# psc3_p8 register map
Vendor: Infineon Technologies; Series: PSC3_P8; File version: 1.0
CPU: CM33 r0p1, little endian, MPU, FPU, DSP, VTOR, 3 interrupt priority bits, 143 interrupts
Registers are 32-bit, read-write, reset 0x0 unless marked. A register's access mark holds for its fields unless they carry their own. Offsets are from the block's base; [hi:lo] are bit positions; lines under a group give offsets from that group; {n}, {i} and the like mark numbered series.

## PPCA_CNFG
Base 0x43000000
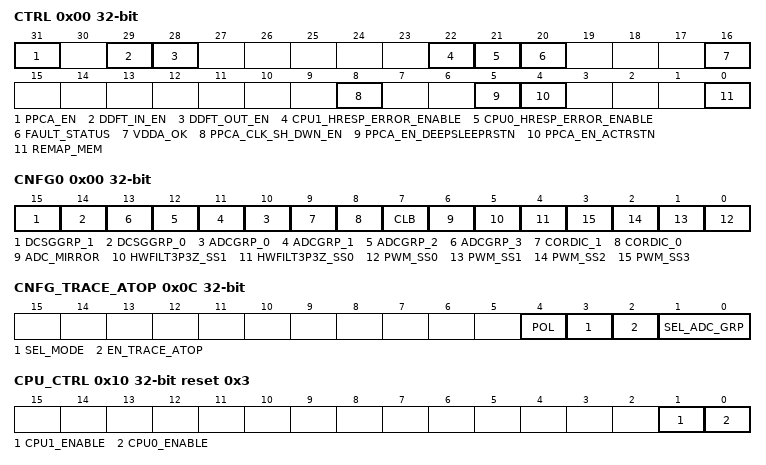
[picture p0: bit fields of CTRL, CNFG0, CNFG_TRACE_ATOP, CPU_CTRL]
0x00 CTRL
  [31] PPCA_EN — PPCA Enable/Disable register 0 = PPCA disabled, all the internal clock are gated, all registers are reset 1 = PPCA enabled
  [29] DDFT_IN_EN — Enable DDFT_IN: 0 = DDFT_IN disable 1 = DDFT_IN enable
  [28] DDFT_OUT_EN — Enable DDFT_OUT: 0 = DDFT_OUT disable 1 = DDFT_OUT enable
  [22] CPU1_HRESP_ERROR_ENABLE — CPU1 HRESP ERROR propagation as Fault Enable Control register 0 = CPU1 HRESP ERROR FAULT Disable 1 = CPU1 HRESP ERROR FAULT Enable
  [21] CPU0_HRESP_ERROR_ENABLE — CPU0 HRESP ERROR propagation as Fault Enable Control register 0 = CPU0 HRESP ERROR FAULT Disable 1 = CPU0 HRESP ERROR FAULT Enable
  [20] FAULT_STATUS write-1-clears — Reflect status of the Fault: 0 = no fault 1 = fault active Writing 1 on this bit clear the fault
  [16] VDDA_OK ro — PPCA VDDA Domain Voltage Status: 0 = VDDA not in the functional operation voltage range 1 = VDDA is in the functional operation voltage range
  [8] PPCA_CLK_SH_DWN_EN — PPCA Clock Shut Down Enable: 0 = Disable Clock Shut Down 1 = Enable Clock Shut Down
  [5] PPCA_EN_DEEPSLEEPRSTN — Enable/Disable PPCA_EN bit to reset PPCA retained logic: 0 = Disable 1 = Enable
  [4] PPCA_EN_ACTRSTN — Enable/Disable PPCA_EN bit to reset PPCA non-retained (active) logic: 0 = Disable 1 = Enable
  [0] REMAP_MEM — PPCA BusMatrix Remap Bit: 0 = Dedicated memories assigned for CPU0 and CPU1 1 = CPU1 memories reassigned to CPU0 memories
0x100 CNFG group
  0x00 CNFG0
    [15] DCSGGRP_1 — PPCA Configuration Register 0 = DCSGGRP_1 assigned to CPU0 1 = DCSGGRP_1 assigned to CPU1
    [14] DCSGGRP_0 — PPCA Configuration Register 0 = DCSGGRP_0 assigned to CPU0 1 = DCSGGRP_0 assigned to CPU1
    [n+10] ADCGRP_{n} (n=0..3) — PPCA Configuration Register 0 = ADCGRP_{n} assigned to CPU0 1 = ADCGRP_{n} assigned to CPU1
    [9] CORDIC_1 — PPCA Configuration Register 0 = CORDIC_1 assigned to CPU0 1 = CORDIC_1 assigned to CPU1
    [8] CORDIC_0 — PPCA Configuration Register 0 = CORDIC_0 assigned to CPU0 1 = CORDIC_0 assigned to CPU1
    [7] CLB — PPCA Configuration Register 0 = CLB assigned to CPU0 1 = CLB assigned to CPU1
    [6] ADC_MIRROR — PPCA Configuration Register 0 = ADC_MIRROR assigned to CPU0 1 = ADC_MIRROR assigned to CPU1
    [5] HWFILT3P3Z_SS1 — PPCA Configuration Register 0 = HWFILT3P3Z_SS1 assigned to CPU0 1 = HWFILT3P3Z_SS1 assigned to CPU1
    [4] HWFILT3P3Z_SS0 — PPCA Configuration Register 0 = HWFILT3P3Z_SS0 assigned to CPU0 1 = HWFILT3P3Z_SS0 assigned to CPU1
    [n] PWM_SS{n} (n=0..3) — PPCA Configuration Register 0 = PWM_SS{n} assigned to CPU0 1 = PWM_SS{n} assigned to CPU1
  0x04 CNFG1
    [31:0] CNFG_PUTY1 — PPCA EPU PU TYPE1 Resources Configuration Register CNFG_PUTY1[i] = 0, assign PUTY1 'i' to CPU0 CNFG_PUTY1[i] = 1, assign PUTY1 'i' to CPU1
  0x08 CNFG2
    [15:0] CNFG_PUTY2 — PPCA EPU Resources PU TYPE2 Configuration Register CNFG_PUTY2[i] = 0, assign PUTY2 'i' to CPU0 CNFG_PUTY2[i] = 1, assign PUTY2 'i' to CPU1
  0x0C CNFG_TRACE_ATOP
    [4] POL — Invert polarity of STB_STRETCH signal: 0 = Rising edge aligned with the data change 1 = Falling edge aligned with data chnage
    [3] SEL_MODE — Select TRACE_ATOP Mode: 0 = TRACE_ATOP test mode (adc data splitted into two nibble, each one of 6 bit) 1 = TRACE_ATOP functional mode (adc data planar exported)
    [2] EN_TRACE_ATOP — Enable TRACE_ATOP: 0 = TRACE_ATOP disable 1 = TRACE_ATOP enable
    [1:0] SEL_ADC_GRP — Select ADC Group source for TRACE_ATOP: 0 = ADC_GRP0 1 = ADC_GRP1 2 = ADC_GRP2 3 = ADC_GRP3
  0x10 CPU_CTRL reset 0x3
    [1] CPU1_ENABLE — CPU1 Enable Control register 0 = CPU1 Clock disable 1 = CPU0 Clock Enable
    [0] CPU0_ENABLE — CPU0 Enable Control register 0 = CPU0 Clock Disable 1 = CPU0 Clock Enable
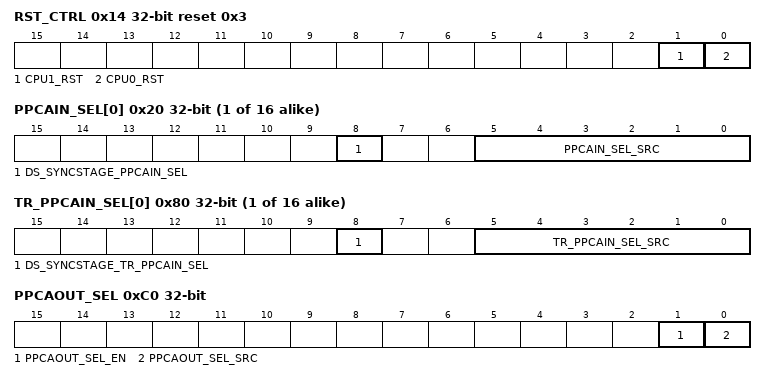
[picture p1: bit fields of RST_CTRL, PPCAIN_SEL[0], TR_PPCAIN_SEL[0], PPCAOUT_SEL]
  0x14 RST_CTRL reset 0x3
    [1] CPU1_RST — CPU1 Reset Control bit: 0 = Reset asserted 1 = Reset released
    [0] CPU0_RST — CPU0 Reset Control bit: 0 = CPU under reset 1 = CPU reset release
  {0x20+4j} PPCAIN_SEL[{j}] (j=0..15)
    [8] DS_SYNCSTAGE_PPCAIN_SEL — Disable PPCA Input Selector Output Synchronizer Stage 0 = Synchronizer Stage Enabled (2 FF in sequence) 1 = Synchronizer Stage Disabled (only 1 FF)
    [5:0] PPCAIN_SEL_SRC — PPCA Input Selector Source
  {0x80+4j} TR_PPCAIN_SEL[{j}] (j=0..15)
    [8] DS_SYNCSTAGE_TR_PPCAIN_SEL — Disable PPCA Trigger Input Selector Output Synchronizer Stage 0 = Synchronizer Stage Enabled (2 FF in sequence) 1 = Synchronizer Stage Disabled (only 1 FF)
    [5:0] TR_PPCAIN_SEL_SRC — PPCA Trigger Input Selector Source
  0xC0 PPCAOUT_SEL
    [1] PPCAOUT_SEL_EN — PPCA Output Selector Enabled 0 = Disabled (output se to 0) 1 = Enabled
    [0] PPCAOUT_SEL_SRC — PPCA Output Selector Source 0 = TCPWM output 1 = CLB output
  {0xE0+4j} DDFTOUT_SEL[{j}] (j=0..1)
    [8:0] DDFTOUT_SEL_SRC — PPCA DDFT Output Selector
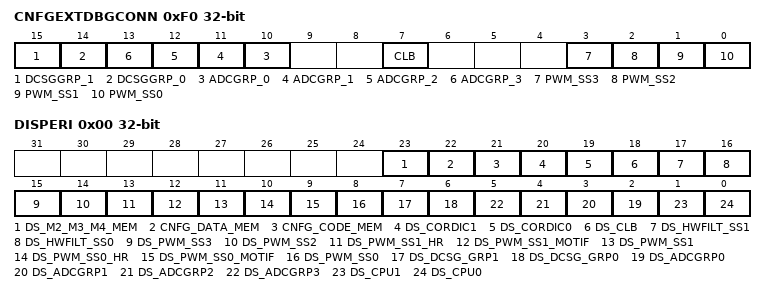
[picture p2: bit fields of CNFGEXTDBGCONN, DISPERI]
  0xF0 CNFGEXTDBGCONN
    [15] DCSGGRP_1 — PPCA EXT AHB IF Debug Conn Configuration Register 0 = DCSGGRP_1 assigned to Main CPU 1 = DCSGGRP_1 assigned to PPCA CPUs
    [14] DCSGGRP_0 — PPCA EXT AHB IF Debug Conn Configuration Register 0 = DCSGGRP_0 assigned to Main CPU 1 = DCSGGRP_0 assigned to PPCA CPUs
    [n+10] ADCGRP_{n} (n=0..3) — PPCA EXT AHB IF Debug Conn Configuration Register 0 = ADCGRP_{n} assigned to Main CPU 1 = ADCGRP_{n} assigned to PPCA CPUs
    [7] CLB — PPCA Configuration Register for ExtAHB Master IF 0 = CLB assigned to Main CPU 1 = CLB assigned to PPCA CPUs
    [3] PWM_SS3 — PPCA EXT AHB IF Debug Conn Configuration Register 0 = PWM_SS3 assigned to Main CPU 1 = PWM_SS3 assigned to PPCA CPUs
    [2] PWM_SS2 — PPCA EXT AHB IF Debug Conn Configuration Register 0 = PWM_SS2 assigned to Main CPU 1 = PWM_SS2 assigned to PPCA CPUs
    [1] PWM_SS1 — PPCA EXT AHB IF Debug Conn Configuration Register 0 = PWM_SS1 assigned to Main CPU 1 = PWM_SS1 assigned to PPCA CPUs
    [0] PWM_SS0 — PPCA EXT AHB IF Debug Conn Configuration Register 0 = PWM_SS0 assigned to MainCPU 1 = PWM_SS0 assigned to PPCA CPUs
  0xF4 PPCAIO_IN_MON ro
    [15:0] PPCAIO_IN_MON — PPCAIO_IN Monitor register (it reflect the status of PPCAIO Input signals synchronized with PPCA CLK)
  0xF8 SCRATCH0
    [31:0] SCRATCH0 — PPCA Scratch register
  0xFC SCRATCH1
    [31:0] SCRATCH1 — PPCA Scratch register
{0x300+0x10*i} S2IRQ[{i}] (i=0..6) group
  0x00 INTR — Interrupt Request Register
    [0] INTR write-1-clears — Interrupt requests
  0x04 INTR_SET — Interrupt Set Request Register
    [0] INTR_SET write-1-sets — Write INTR_SET field with '1' to set corresponding INTR field. When read, this register reflects the interrupt request register. That is the INTR register.
  0x08 INTR_MASK — Interrupt Mask Register
    [0] INTR_MASK — Mask for corresponding field in INTR register.
  0x0C INTR_MASKED ro — Interrupt Masked Register
    [0] INTR_MASKED — Logical AND of corresponding interrupt request (INTR) and mask fields (INTR_MASK).
0x400 ADCM group
  {0x0+4j} ADC_DATA[{j}] (j=0..47) ro
    [31:0] ADC_DATA — ADCs DATA Channel (ADC0_DATA, ADC0_AUX_DATA, ADC0_ALT_AUX_DATA, ADC1_DATA, ADC2_DATA, ADC3_DATA, ADC3_AUX_DATA)
0x800 DISPERI group
  0x00 DISPERI
    [23] DS_M2_M3_M4_MEM — Disable memory M2, M3, M4 (Light Configuration) 1 = M2, M3, M4 memories accesses are disabled 0 = M2, M3, M4 memories accesses are allowed
    [22] CNFG_DATA_MEM — Reduce CPUs Data Mem by half (shared mem not included) 1 = Data Mem is reduced by half 0 = Data Mem is not reduced
    [21] CNFG_CODE_MEM — Reflect instantiated CPUs Code Mem Size 1 = Code Mem is 32kB 0 = Code Mem is 64kB
    [20] DS_CORDIC1 — disable 2nd CORDIC 1 = 2nd CORDIC AHB memory space access is disabled 0 = 2nd CORDIC AHB memory space access is enabled
    [19] DS_CORDIC0 — disable 1st CORDIC 1 = 1st CORDIC AHB memory space access is disabled 0 = 1st CORDIC AHB memory space access is enabled
    [18] DS_CLB — disable CLB 1 = CLB AHB memory space access is disabled 0 = CLB AHB memory space access is enabled
    [17] DS_HWFILT_SS1 — disable HWFILT3P3Z SS1 1 = HWFILT3P3Z SS1 AHB memory space access is disabled 0 = HWFILT3P3Z SS1 AHB memory space access is enabled
    [16] DS_HWFILT_SS0 — disable HWFILT3P3Z SS0 1 = HWFILT3P3Z SS0 AHB memory space access is disabled 0 = HWFILT3P3Z SS0 AHB memory space access is enabled
    [15] DS_PWM_SS3 — disablePWM SS3 1 = PWM SS3 AHB memory space access is disabled 0 = PWM SS3 AHB memory space access is enabled
    [14] DS_PWM_SS2 — disablePWM SS2 1 = PWM SS2 AHB memory space access is disabled 0 = PWM SS2 AHB memory space access is enabled
    [13] DS_PWM_SS1_HR — disablePWM SS1 HR 1 = PWM SS1 HR AHB memory space access is disabled 0 = PWM SS1 HR AHB memory space access is enabled
    [12] DS_PWM_SS1_MOTIF — disablePWM SS1 MOTIF 1 = PWM SS1 MOTIF AHB memory space access is disabled 0 = PWM SS1 MOTIF AHB memory space access is enabled
    [11] DS_PWM_SS1 — disablePWM SS1 1 = PWM SS1 AHB memory space access is disabled 0 = PWM SS1 AHB memory space access is enabled
    [10] DS_PWM_SS0_HR — disablePWM SS0 HR 1 = PWM SS0 HR AHB memory space access is disabled 0 = PWM SS0 HR AHB memory space access is enabled
    [9] DS_PWM_SS0_MOTIF — disablePWM SS0 MOTIF 1 = PWM SS0 MOTIF AHB memory space access is disabled 0 = PWM SS0 MOTIF AHB memory space access is enabled
    [8] DS_PWM_SS0 — disablePWM SS0 1 = PWM SS0 AHB memory space access is disabled 0 = PWM SS0 AHB memory space access is enabled
    [7] DS_DCSG_GRP1 — disable GCSG GROUP 1 1 = DCSGGRP1 AHB memory space access is disabled 0 = DCSGGRP1 AHB memory space access is enabled
    [6] DS_DCSG_GRP0 — disable GCSG GROUP 0 1 = DCSGGRP0 AHB memory space access is disabled 0 = DCSGGRP0 AHB memory space access is enabled
    [n+2] DS_ADCGRP{n} (n=0..3) — disable ADC GROUP {n} 1 = ADCGRP{n} AHB memory space access is disabled 0 = ADCGRP{n} AHB memory space access is enabled
    [1] DS_CPU1 — disable CPU1 1 = CPU1 is disabled (i.e. Is kept under reset) 0 = CPU1 is enabled (i.e. cpu_reset is controlled by CTL register)
    [0] DS_CPU0 — disable CPU0 1 = CPU0 is disable (i.e. Is kept under reset) 0 = CPU0 is enabled (i.e. cpu_reset is controlled by CTL register)

## Notices in the file
(c) 2016-2026, Infineon Technologies AG or an affiliate of
Infineon Technologies AG.
SPDX-License-Identifier: Apache-2.0
Licensed under the Apache License, Version 2.0 (the "License");
you may not use this file except in compliance with the License.
You may obtain a copy of the License at
http://www.apache.org/licenses/LICENSE-2.0
Unless required by applicable law or agreed to in writing, software
distributed under the License is distributed on an "AS IS" BASIS,
WITHOUT WARRANTIES OR CONDITIONS OF ANY KIND, either express or implied.
See the License for the specific language governing permissions and
limitations under the License.
